VERSION "1.0"

NS_ :

BS_:

BU_: MASTER_NODE MOTOR_01 HEAT_01 THERM_01 THERM_02

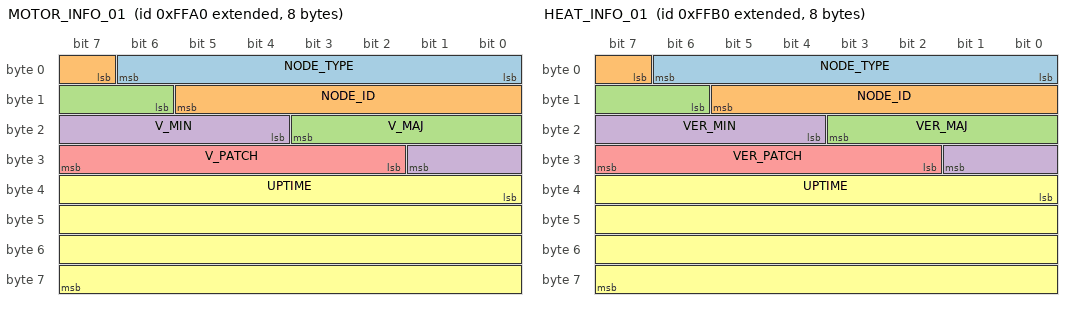
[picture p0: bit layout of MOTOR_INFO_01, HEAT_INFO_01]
BO_ 2147549088 MOTOR_INFO_01: 8 MASTER_NODE
  SG_ NODE_TYPE : 0|7@1+ (1,0) [0|127] "" MASTER_NODE
  SG_ NODE_ID : 7|7@1+ (1,0) [0|127] "" MASTER_NODE
  SG_ V_MAJ : 14|6@1+ (1,0) [0|63] "" MASTER_NODE
  SG_ V_MIN : 20|6@1+ (1,0) [0|63] "" MASTER_NODE
  SG_ V_PATCH : 26|6@1+ (1,0) [0|63] "" MASTER_NODE
  SG_ UPTIME : 32|32@1+ (1,0) [0|4294967295] "" MASTER_NODE

BO_ 2147549089 MOTOR_CMD_01: 8 MASTER_NODE
  SG_ RELAY_STATE : 0|1@1+ (1,0) [0|1] "" MOTOR_01

BO_ 2147549090 MOTOR_STATE_01: 8 MOTOR_01
  SG_ RELAY_STATE : 0|1@1+ (1,0) [0|1] "" MASTER_NODE

BO_ 2147549104 HEAT_INFO_01: 8 HEAT_01
  SG_ NODE_TYPE : 0|7@1+ (1,0) [0|127] "" MASTER_NODE
  SG_ NODE_ID : 7|7@1+ (1,0) [0|127] "" MASTER_NODE
  SG_ VER_MAJ : 14|6@1+ (1,0) [0|63] "" MASTER_NODE
  SG_ VER_MIN : 20|6@1+ (1,0) [0|63] "" MASTER_NODE
  SG_ VER_PATCH : 26|6@1+ (1,0) [0|63] "" MASTER_NODE
  SG_ UPTIME : 32|32@1+ (1,0) [0|4294967295] "" MASTER_NODE

BO_ 2147549105 HEAT_CMD_01: 8 MASTER_NODE
  SG_ RELAY_STATE : 0|1@1+ (1,0) [0|1] "" HEAT_01

BO_ 2147549106 HEAT_STATE_01: 8 HEAT_01
  SG_ RELAY_STATE : 0|1@1+ (1,0) [0|1] "" MASTER_NODE

BO_ 2147549121 THERM_STATE_01: 8 THERM_01
  SG_ TEMP_C : 0|16@1- (0.01,0) [-327.68|327.67] "C" MASTER_NODE
  SG_ TEMP_V : 16|16@1+ (0.001,0) [0|65.535] "V" MASTER_NODE

 BO_ 2147549122 THERM_STATE_02: 8 THERM_02
  SG_ TEMP_C : 0|16@1- (0.01,0) [-327.68|327.67] "C" MASTER_NODE
  SG_ TEMP_V : 16|16@1+ (0.001,0) [0|65.535] "V" MASTER_NODE
